AUTOSAR XML (schema 4.0)
package /T/If
  sender receiver interface Status
    data locked
  sender receiver interface Summary
    data allLocked
  client server interface Cmd
    operation setLock
package /T/Swc
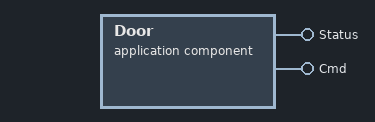
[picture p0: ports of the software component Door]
  application sw component type Door
    provide port Status: provided-interface=Status
    provide port Cmd: provided-interface=Cmd
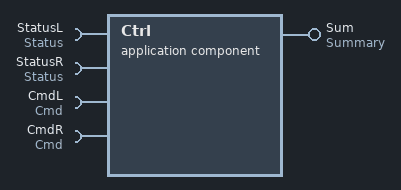
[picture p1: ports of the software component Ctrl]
  application sw component type Ctrl
    4 x require port:
      StatusL: required-interface=Status
      StatusR: required-interface=Status
      CmdL: required-interface=Cmd
      CmdR: required-interface=Cmd
    provide port Sum: provided-interface=Summary
  composition sw component type Top
    provide port Sum: provided-interface=Summary
    component dl: type=Door
    component dr: type=Door
    component ctrl: type=Ctrl
    connect dl.Status -> ctrl.StatusL
    connect dr.Status -> ctrl.StatusR
    connect dl.Cmd -> ctrl.CmdL
    connect dr.Cmd -> ctrl.CmdR
    delegate ctrl.Sum <-> outer port Top/Sum
